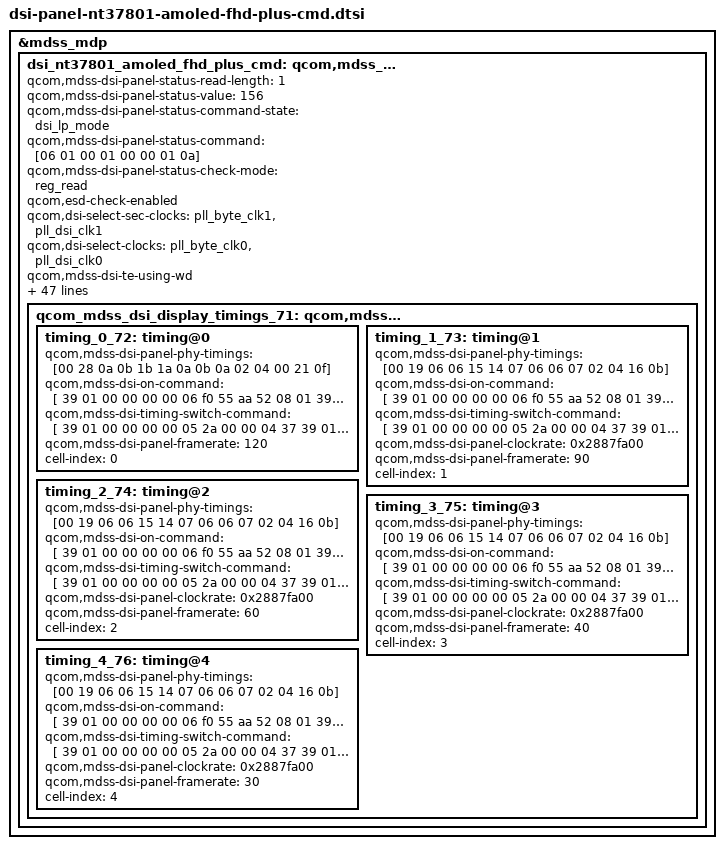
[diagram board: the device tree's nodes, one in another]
/* Xiaomi 17 Ultra panel configuration, OS4.0.7.0.XPACNXM. */

&mdss_mdp {
	dsi_nt37801_amoled_fhd_plus_cmd: qcom,mdss_dsi_nt37801_fhd_plus_cmd {
		qcom,mdss-dsi-panel-status-read-length = <1>;
		qcom,mdss-dsi-panel-status-value = <156>;
		qcom,mdss-dsi-panel-status-command-state = "dsi_lp_mode";
		qcom,mdss-dsi-panel-status-command = [06 01 00 01 00 00 01 0a];
		qcom,mdss-dsi-panel-status-check-mode = "reg_read";
		qcom,esd-check-enabled;
		qcom,dsi-select-sec-clocks = "pll_byte_clk1", "pll_dsi_clk1";
		qcom,dsi-select-clocks = "pll_byte_clk0", "pll_dsi_clk0";
		qcom,mdss-dsi-te-using-wd;
		qcom,platform-reset-gpio = <&tlmm 98 0>;
		qcom,mdss-dsi-bl-inverted-dbv;
		qcom,mdss-brightness-max-level = <8191>;
		qcom,mdss-dsi-bl-max-level = <4095>;
		qcom,mdss-dsi-bl-min-level = <10>;
		qcom,mdss-dsi-bl-pmic-control-type = "bl_ctrl_dcs";
		qcom,panel-supply-entries = <&dsi_panel_pwr_supply>;
		qcom,mdss-dsi-panel-blackness-level = <10>;
		qcom,mdss-dsi-panel-peak-brightness = <13000000>;
		qcom,mdss-dsi-panel-hdr-color-primaries = <15150 15750 34250 15700 12250 35800 6750 2550>;
		qcom,mdss-dsi-panel-hdr-enabled;
		qcom,spr-pack-type = "pentile";
		qcom,mdss-dsi-te-using-te-pin;
		qcom,mdss-dsi-te-check-enable;
		qcom,mdss-dsi-te-dcs-command = <1>;
		qcom,mdss-dsi-wr-mem-continue = <60>;
		qcom,mdss-dsi-wr-mem-start = <44>;
		qcom,mdss-dsi-te-pin-select = <1>;
		qcom,mdss-dsi-reset-sequence = <1 10 0 10 1 10>;
		qcom,mdss-dsi-mdp-trigger = "none";
		qcom,mdss-dsi-dma-trigger = "trigger_sw";
		qcom,mdss-dsi-lane-3-state;
		qcom,mdss-dsi-lane-2-state;
		qcom,mdss-dsi-lane-1-state;
		qcom,mdss-dsi-lane-0-state;
		qcom,mdss-dsi-bllp-power-mode;
		qcom,mdss-dsi-bllp-eof-power-mode;
		qcom,mdss-dsi-lane-map = "lane_map_0123";
		qcom,mdss-dsi-traffic-mode = "non_burst_sync_event";
		qcom,dsi-sec-phy-num = <1>;
		qcom,dsi-sec-ctrl-num = <1>;
		qcom,dsi-phy-num = <0>;
		qcom,dsi-ctrl-num = <0>;
		qcom,mdss-dsi-border-color = <0>;
		qcom,mdss-dsi-underflow-color = <255>;
		qcom,mdss-dsi-color-order = "rgb_swap_rgb";
		qcom,mdss-dsi-bpp = <24>;
		qcom,mdss-dsi-stream = <0>;
		qcom,mdss-dsi-virtual-channel-id = <0>;
		qcom,mdss-dsi-panel-physical-type = "oled";
		qcom,mdss-dsi-panel-type = "dsi_cmd_mode";
		qcom,mdss-dsi-panel-name = "nt37801 amoled fhd plus cmd mode dsi csot panel with DSC";

		qcom_mdss_dsi_display_timings_71: qcom,mdss-dsi-display-timings {
			timing_0_72: timing@0 {
				#include "dsi-panel-nt37801-amoled-fhd-plus-cmd-common.dtsi"
				qcom,mdss-dsi-panel-phy-timings = [00 28 0a 0b 1b 1a 0a 0b 0a 02 04 00 21 0f];
				qcom,mdss-dsi-on-command = [
					39 01 00 00 00 00 06 f0 55 aa 52 08 01 39 01 00
					00 00 00 02 6f 01 39 01 00 00 00 00 04 c5 0b 0b
					0b 39 01 00 00 00 00 05 ff aa 55 a5 80 39 01 00
					00 00 00 02 6f 02 39 01 00 00 00 00 02 f5 10 39
					01 00 00 00 00 02 6f 1b 39 01 00 00 00 00 02 f4
					55 39 01 00 00 00 00 02 6f 18 39 01 00 00 00 00
					02 f8 19 39 01 00 00 00 00 02 6f 0f 39 01 00 00
					00 00 02 fc 00 39 01 00 00 00 00 05 2a 00 00 04
					37 39 01 00 00 00 00 05 2b 00 00 09 5f 39 01 00
					00 00 00 02 90 03 39 01 00 00 00 00 13 91 89 28
					00 28 c2 00 02 0e 03 dd 00 07 02 77 02 8b 10 f0
					39 01 00 00 00 00 05 ff aa 55 a5 81 39 01 00 00
					00 00 02 6f 23 39 01 00 00 00 00 15 fb 00 01 00
					11 33 33 33 55 57 d0 00 00 44 56 77 78 9a bc dd
					f0 39 01 00 00 00 00 13 93 89 28 00 28 d2 00 02
					25 03 b6 00 07 02 ab 02 8b 10 f0 39 01 00 00 00
					00 13 95 89 28 00 28 d2 00 01 c3 02 fc 00 05 02
					ab 03 d1 10 f0 39 01 00 00 00 00 02 03 00 39 01
					00 00 00 00 02 8f 01 39 01 00 00 00 00 02 6f 06
					39 01 00 00 00 00 02 f3 dc 39 01 00 00 00 00 02
					26 00 39 01 00 00 00 00 02 35 00 39 01 00 00 00
					00 05 3b 00 18 00 10 39 01 00 00 00 00 02 53 20
					39 01 00 00 00 00 07 51 07 ff 07 ff 0f ff 39 01
					00 00 00 00 02 5a 01 39 01 00 00 00 00 02 5f 00
					39 01 00 00 00 00 02 9c 01 05 01 00 00 00 00 01
					2c 39 01 00 00 00 00 02 2f 00 05 01 00 00 78 00
					01 11 05 01 00 00 14 00 01 29
				];
				qcom,mdss-dsi-timing-switch-command = [
					39 01 00 00 00 00 05 2a 00 00 04 37 39 01 00 00
					00 00 05 2b 00 00 09 5f 39 01 00 00 00 00 02 8f
					01 39 01 00 00 00 00 02 2f 00 39 01 00 00 00 00
					02 26 00 39 01 00 00 00 00 06 f0 55 aa 52 08 00
					39 01 00 00 00 00 06 c0 54 c0 00 21 43 39 01 00
					00 00 00 06 f0 55 aa 52 08 02 39 01 00 00 00 00
					02 cc 30 39 01 00 00 00 00 02 ce 01 39 01 00 00
					20 00 02 cc 00
				];
				qcom,mdss-dsi-panel-framerate = <120>;
				cell-index = <0>;
			};

			timing_1_73: timing@1 {
				#include "dsi-panel-nt37801-amoled-fhd-plus-cmd-common.dtsi"
				qcom,mdss-dsi-panel-phy-timings = [00 19 06 06 15 14 07 06 06 07 02 04 16 0b];
				qcom,mdss-dsi-on-command = [
					39 01 00 00 00 00 06 f0 55 aa 52 08 01 39 01 00
					00 00 00 02 6f 01 39 01 00 00 00 00 04 c5 0b 0b
					0b 39 01 00 00 00 00 05 ff aa 55 a5 80 39 01 00
					00 00 00 02 6f 06 39 01 00 00 00 00 02 f3 dc 39
					01 00 00 00 00 02 6f 02 39 01 00 00 00 00 02 f5
					10 39 01 00 00 00 00 02 6f 1b 39 01 00 00 00 00
					02 f4 55 39 01 00 00 00 00 02 6f 18 39 01 00 00
					00 00 02 f8 19 39 01 00 00 00 00 02 6f 0f 39 01
					00 00 00 00 02 fc 00 39 01 00 00 00 00 05 2a 00
					00 04 37 39 01 00 00 00 00 05 2b 00 00 09 5f 39
					01 00 00 00 00 02 90 03 39 01 00 00 00 00 13 91
					89 28 00 28 c2 00 02 0e 03 dd 00 07 02 77 02 8b
					10 f0 39 01 00 00 00 00 05 ff aa 55 a5 81 39 01
					00 00 00 00 02 6f 23 39 01 00 00 00 00 15 fb 00
					01 00 11 33 33 33 55 57 d0 00 00 44 56 77 78 9a
					bc dd f0 39 01 00 00 00 00 02 35 00 39 01 00 00
					00 00 05 3b 00 18 00 10 39 01 00 00 00 00 02 53
					20 39 01 00 00 00 00 07 51 07 ff 07 ff 0f ff 39
					01 00 00 00 00 02 5a 01 39 01 00 00 00 00 02 5f
					00 39 01 00 00 00 00 02 9c 01 05 01 00 00 00 00
					01 2c 39 01 00 00 00 00 02 8f 01 39 01 00 00 00
					00 02 2f 01 39 01 00 00 00 00 02 26 01 39 01 00
					00 00 00 06 f0 55 aa 52 08 00 39 01 00 00 00 00
					06 c0 54 c0 00 24 45 39 01 00 00 00 00 06 f0 55
					aa 52 08 02 39 01 00 00 00 00 02 cc 30 39 01 00
					00 00 00 02 ce 01 39 01 00 00 20 00 02 cc 00 39
					01 00 00 00 00 06 f0 55 aa 52 08 01 39 01 00 00
					00 00 05 b2 55 01 ff 03 05 01 00 00 78 00 01 11
					05 01 00 00 14 00 01 29
				];
				qcom,mdss-dsi-timing-switch-command = [
					39 01 00 00 00 00 05 2a 00 00 04 37 39 01 00 00
					00 00 05 2b 00 00 09 5f 39 01 00 00 00 00 02 8f
					01 39 01 00 00 00 00 02 2f 01 39 01 00 00 00 00
					02 26 01 39 01 00 00 00 00 06 f0 55 aa 52 08 00
					39 01 00 00 00 00 06 c0 54 c0 00 24 45 39 01 00
					00 00 00 06 f0 55 aa 52 08 02 39 01 00 00 00 00
					02 cc 30 39 01 00 00 00 00 02 ce 01 39 01 00 00
					20 00 02 cc 00
				];
				qcom,mdss-dsi-panel-clockrate = <0x2887fa00>;
				qcom,mdss-dsi-panel-framerate = <90>;
				cell-index = <1>;
			};

			timing_2_74: timing@2 {
				#include "dsi-panel-nt37801-amoled-fhd-plus-cmd-common.dtsi"
				qcom,mdss-dsi-panel-phy-timings = [00 19 06 06 15 14 07 06 06 07 02 04 16 0b];
				qcom,mdss-dsi-on-command = [
					39 01 00 00 00 00 06 f0 55 aa 52 08 01 39 01 00
					00 00 00 02 6f 01 39 01 00 00 00 00 04 c5 0b 0b
					0b 39 01 00 00 00 00 05 ff aa 55 a5 80 39 01 00
					00 00 00 02 6f 02 39 01 00 00 00 00 02 f5 10 39
					01 00 00 00 00 02 6f 1b 39 01 00 00 00 00 02 f4
					55 39 01 00 00 00 00 02 6f 18 39 01 00 00 00 00
					02 f8 19 39 01 00 00 00 00 02 6f 0f 39 01 00 00
					00 00 02 fc 00 39 01 00 00 00 00 05 2a 00 00 04
					37 39 01 00 00 00 00 05 2b 00 00 09 5f 39 01 00
					00 00 00 02 90 03 39 01 00 00 00 00 13 91 89 28
					00 28 c2 00 02 0e 03 dd 00 07 02 77 02 8b 10 f0
					39 01 00 00 00 00 05 ff aa 55 a5 81 39 01 00 00
					00 00 02 6f 23 39 01 00 00 00 00 15 fb 00 01 00
					11 33 33 33 55 57 d0 00 00 44 56 77 78 9a bc dd
					f0 39 01 00 00 00 00 02 6f 06 39 01 00 00 00 00
					02 f3 dc 39 01 00 00 00 00 02 26 00 39 01 00 00
					00 00 02 35 00 39 01 00 00 00 00 05 3b 00 18 00
					10 39 01 00 00 00 00 02 53 20 39 01 00 00 00 00
					07 51 07 ff 07 ff 0f ff 39 01 00 00 00 00 02 5a
					01 39 01 00 00 00 00 02 5f 00 39 01 00 00 00 00
					02 9c 01 05 01 00 00 00 00 01 2c 39 01 00 00 00
					00 02 8f 01 39 01 00 00 00 00 02 2f 00 39 01 00
					00 00 00 02 26 01 39 01 00 00 00 00 02 5a 01 39
					01 00 00 00 00 02 2f 30 39 01 00 00 00 00 06 f0
					55 aa 52 08 00 39 01 00 00 00 00 02 6f 1c 39 01
					00 00 00 00 09 ba 91 01 01 00 01 01 01 00 39 01
					00 00 00 00 06 f0 55 aa 52 08 00 39 01 00 00 00
					00 06 c0 54 c0 00 21 43 39 01 00 00 00 00 06 f0
					55 aa 52 08 02 39 01 00 00 00 00 02 cc 30 39 01
					00 00 00 00 02 ce 01 39 01 00 00 20 00 02 cc 00
					39 01 00 00 00 00 06 f0 55 aa 52 08 01 39 01 00
					00 00 00 05 b2 55 01 ff 03 05 01 00 00 78 00 01
					11 05 01 00 00 14 00 01 29
				];
				qcom,mdss-dsi-timing-switch-command = [
					39 01 00 00 00 00 05 2a 00 00 04 37 39 01 00 00
					00 00 05 2b 00 00 09 5f 39 01 00 00 00 00 02 8f
					01 39 01 00 00 00 00 02 2f 00 39 01 00 00 00 00
					02 26 01 39 01 00 00 00 00 02 5a 01 39 01 00 00
					00 00 02 2f 30 39 01 00 00 00 00 06 f0 55 aa 52
					08 00 39 01 00 00 00 00 02 6f 1c 39 01 00 00 00
					00 09 ba 91 01 01 00 01 01 01 00 39 01 00 00 00
					00 06 f0 55 aa 52 08 00 39 01 00 00 00 00 06 c0
					54 c0 00 21 43 39 01 00 00 00 00 06 f0 55 aa 52
					08 02 39 01 00 00 00 00 02 cc 30 39 01 00 00 00
					00 02 ce 01 39 01 00 00 20 00 02 cc 00
				];
				qcom,mdss-dsi-panel-clockrate = <0x2887fa00>;
				qcom,mdss-dsi-panel-framerate = <60>;
				cell-index = <2>;
			};

			timing_3_75: timing@3 {
				#include "dsi-panel-nt37801-amoled-fhd-plus-cmd-common.dtsi"
				qcom,mdss-dsi-panel-phy-timings = [00 19 06 06 15 14 07 06 06 07 02 04 16 0b];
				qcom,mdss-dsi-on-command = [
					39 01 00 00 00 00 06 f0 55 aa 52 08 01 39 01 00
					00 00 00 02 6f 01 39 01 00 00 00 00 04 c5 0b 0b
					0b 39 01 00 00 00 00 05 ff aa 55 a5 80 39 01 00
					00 00 00 02 6f 02 39 01 00 00 00 00 02 f5 10 39
					01 00 00 00 00 02 6f 1b 39 01 00 00 00 00 02 f4
					55 39 01 00 00 00 00 02 6f 18 39 01 00 00 00 00
					02 f8 19 39 01 00 00 00 00 02 6f 0f 39 01 00 00
					00 00 02 fc 00 39 01 00 00 00 00 05 2a 00 00 04
					37 39 01 00 00 00 00 05 2b 00 00 09 5f 39 01 00
					00 00 00 02 90 03 39 01 00 00 00 00 13 91 89 28
					00 28 c2 00 02 0e 03 dd 00 07 02 77 02 8b 10 f0
					39 01 00 00 00 00 05 ff aa 55 a5 81 39 01 00 00
					00 00 02 6f 23 39 01 00 00 00 00 15 fb 00 01 00
					11 33 33 33 55 57 d0 00 00 44 56 77 78 9a bc dd
					f0 39 01 00 00 00 00 02 6f 06 39 01 00 00 00 00
					02 f3 dc 39 01 00 00 00 00 02 26 00 39 01 00 00
					00 00 02 35 00 39 01 00 00 00 00 05 3b 00 18 00
					10 39 01 00 00 00 00 02 53 20 39 01 00 00 00 00
					07 51 07 ff 07 ff 0f ff 39 01 00 00 00 00 02 5a
					01 39 01 00 00 00 00 02 5f 00 39 01 00 00 00 00
					02 9c 01 05 01 00 00 00 00 01 2c 39 01 00 00 00
					00 02 8f 01 39 01 00 00 00 00 02 2f 00 39 01 00
					00 00 00 02 26 01 39 01 00 00 00 00 02 5a 01 39
					01 00 00 00 00 02 2f 30 39 01 00 00 00 00 06 f0
					55 aa 52 08 00 39 01 00 00 00 00 02 6f 1c 39 01
					00 00 00 00 09 ba 91 02 02 00 01 02 02 00 39 01
					00 00 00 00 06 f0 55 aa 52 08 00 39 01 00 00 00
					00 06 c0 54 c0 00 21 43 39 01 00 00 00 00 06 f0
					55 aa 52 08 02 39 01 00 00 00 00 02 cc 30 39 01
					00 00 00 00 02 ce 01 39 01 00 00 20 00 02 cc 00
					39 01 00 00 00 00 06 f0 55 aa 52 08 01 39 01 00
					00 00 00 05 b2 55 01 ff 03 05 01 00 00 78 00 01
					11 05 01 00 00 14 00 01 29
				];
				qcom,mdss-dsi-timing-switch-command = [
					39 01 00 00 00 00 05 2a 00 00 04 37 39 01 00 00
					00 00 05 2b 00 00 09 5f 39 01 00 00 00 00 02 8f
					01 39 01 00 00 00 00 02 2f 00 39 01 00 00 00 00
					02 26 01 39 01 00 00 00 00 02 5a 01 39 01 00 00
					00 00 02 2f 30 39 01 00 00 00 00 06 f0 55 aa 52
					08 00 39 01 00 00 00 00 02 6f 1c 39 01 00 00 00
					00 09 ba 91 02 02 00 01 02 02 00 39 01 00 00 00
					00 06 f0 55 aa 52 08 00 39 01 00 00 00 00 06 c0
					54 c0 00 21 43 39 01 00 00 00 00 06 f0 55 aa 52
					08 02 39 01 00 00 00 00 02 cc 30 39 01 00 00 00
					00 02 ce 01 39 01 00 00 20 00 02 cc 00
				];
				qcom,mdss-dsi-panel-clockrate = <0x2887fa00>;
				qcom,mdss-dsi-panel-framerate = <40>;
				cell-index = <3>;
			};

			timing_4_76: timing@4 {
				#include "dsi-panel-nt37801-amoled-fhd-plus-cmd-common.dtsi"
				qcom,mdss-dsi-panel-phy-timings = [00 19 06 06 15 14 07 06 06 07 02 04 16 0b];
				qcom,mdss-dsi-on-command = [
					39 01 00 00 00 00 06 f0 55 aa 52 08 01 39 01 00
					00 00 00 02 6f 01 39 01 00 00 00 00 04 c5 0b 0b
					0b 39 01 00 00 00 00 05 ff aa 55 a5 80 39 01 00
					00 00 00 02 6f 02 39 01 00 00 00 00 02 f5 10 39
					01 00 00 00 00 02 6f 1b 39 01 00 00 00 00 02 f4
					55 39 01 00 00 00 00 02 6f 18 39 01 00 00 00 00
					02 f8 19 39 01 00 00 00 00 02 6f 0f 39 01 00 00
					00 00 02 fc 00 39 01 00 00 00 00 05 2a 00 00 04
					37 39 01 00 00 00 00 05 2b 00 00 09 5f 39 01 00
					00 00 00 02 90 03 39 01 00 00 00 00 13 91 89 28
					00 28 c2 00 02 0e 03 dd 00 07 02 77 02 8b 10 f0
					39 01 00 00 00 00 05 ff aa 55 a5 81 39 01 00 00
					00 00 02 6f 23 39 01 00 00 00 00 15 fb 00 01 00
					11 33 33 33 55 57 d0 00 00 44 56 77 78 9a bc dd
					f0 39 01 00 00 00 00 02 6f 06 39 01 00 00 00 00
					02 f3 dc 39 01 00 00 00 00 02 26 00 39 01 00 00
					00 00 02 35 00 39 01 00 00 00 00 05 3b 00 18 00
					10 39 01 00 00 00 00 02 53 20 39 01 00 00 00 00
					07 51 07 ff 07 ff 0f ff 39 01 00 00 00 00 02 5a
					01 39 01 00 00 00 00 02 5f 00 39 01 00 00 00 00
					02 9c 01 05 01 00 00 00 00 01 2c 39 01 00 00 00
					00 02 8f 01 39 01 00 00 00 00 02 2f 00 39 01 00
					00 00 00 02 26 01 39 01 00 00 00 00 02 5a 01 39
					01 00 00 00 00 02 2f 30 39 01 00 00 00 00 06 f0
					55 aa 52 08 00 39 01 00 00 00 00 02 6f 1c 39 01
					00 00 00 00 09 ba 91 03 03 00 01 03 03 00 39 01
					00 00 00 00 06 f0 55 aa 52 08 00 39 01 00 00 00
					00 06 c0 54 c0 00 21 43 39 01 00 00 00 00 06 f0
					55 aa 52 08 02 39 01 00 00 00 00 02 cc 30 39 01
					00 00 00 00 02 ce 01 39 01 00 00 20 00 02 cc 00
					39 01 00 00 00 00 06 f0 55 aa 52 08 01 39 01 00
					00 00 00 05 b2 55 01 ff 03 05 01 00 00 78 00 01
					11 05 01 00 00 14 00 01 29
				];
				qcom,mdss-dsi-timing-switch-command = [
					39 01 00 00 00 00 05 2a 00 00 04 37 39 01 00 00
					00 00 05 2b 00 00 09 5f 39 01 00 00 00 00 02 8f
					01 39 01 00 00 00 00 02 2f 00 39 01 00 00 00 00
					02 26 01 39 01 00 00 00 00 02 5a 01 39 01 00 00
					00 00 02 2f 30 39 01 00 00 00 00 06 f0 55 aa 52
					08 00 39 01 00 00 00 00 02 6f 1c 39 01 00 00 00
					00 09 ba 91 03 03 00 01 03 03 00 39 01 00 00 00
					00 06 f0 55 aa 52 08 00 39 01 00 00 00 00 06 c0
					54 c0 00 21 43 39 01 00 00 00 00 06 f0 55 aa 52
					08 02 39 01 00 00 00 00 02 cc 30 39 01 00 00 00
					00 02 ce 01 39 01 00 00 20 00 02 cc 00
				];
				qcom,mdss-dsi-panel-clockrate = <0x2887fa00>;
				qcom,mdss-dsi-panel-framerate = <30>;
				cell-index = <4>;
			};
		};
	};
};
